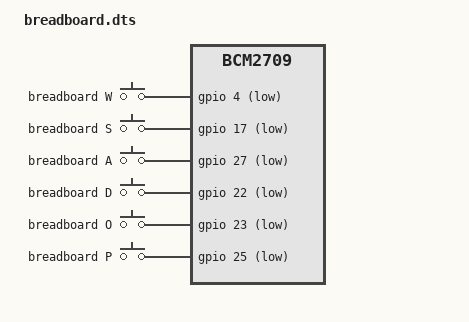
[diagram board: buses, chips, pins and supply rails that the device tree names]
/dts-v1/;
    /plugin/;
    / {
       compatible = "brcm,bcm2835", "brcm,bcm2708", "brcm,bcm2709";
       
       fragment@0 {
          target-path = "/";
          __overlay__ {
             keypad: breadboard_keys {
                compatible = "gpio-keys";
                #address-cells = <1>;
                #size-cells = <0>;
                button@4 {
                   label = "breadboard W";
                   linux,code = <17>;
                   gpios = <&gpio 4 1>;
                };
                button@17 {
                   label = "breadboard S";
                   linux,code = <31>;
                   gpios = <&gpio 17 1>;
                };
                button@27 {
                   label = "breadboard A";
                   linux,code = <30>;
                   gpios = <&gpio 27 1>;
                };
                button@22 {
                   label = "breadboard D";
                   linux,code = <32>;
                   gpios = <&gpio 22 1>;
                };
                button@23 {
                   label = "breadboard O";
                   linux,code = <24>;
                   gpios = <&gpio 23 1>;
                };
                button@25 {
                   label = "breadboard P";
                   linux,code = <25>;
                   gpios = <&gpio 25 1>;
                };
             };
          };
       };
    };
